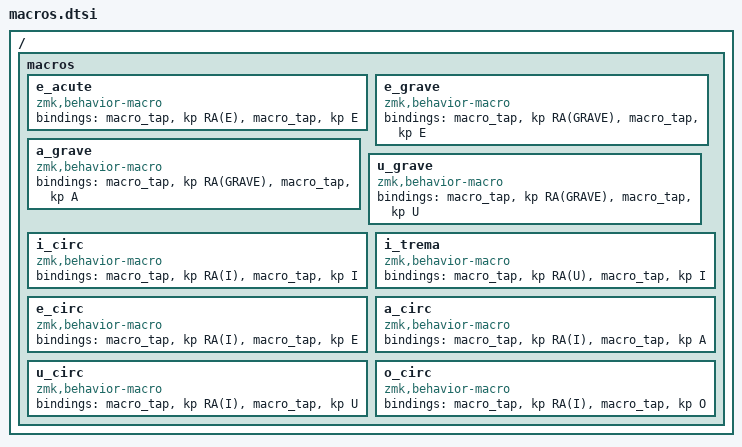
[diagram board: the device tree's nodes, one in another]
// TODO -> Add Windows macros and mark those as MacOS macros

/ {
    macros {
        ///////////////////////////////////
        // ACCENTS
        ///////////////////////////////////
        e_acute: e_acute{ // é
            compatible = "zmk,behavior-macro";
            #binding-cells = <0>;
            bindings
                = <&macro_tap &kp RA(E)>
                , <&macro_tap &kp E>
                ;
        };

        e_grave: e_grave{ // è
            compatible = "zmk,behavior-macro";
            #binding-cells = <0>;
            bindings
                = <&macro_tap &kp RA(GRAVE)>
                , <&macro_tap &kp E>
                ;
        };

        a_grave: a_grave{ // à
            compatible = "zmk,behavior-macro";
            #binding-cells = <0>;
            bindings
                = <&macro_tap &kp RA(GRAVE)>
                , <&macro_tap &kp A>
                ;
        };

        u_grave: u_grave{ // ù
            compatible = "zmk,behavior-macro";
            #binding-cells = <0>;
            bindings
                = <&macro_tap &kp RA(GRAVE)>
                , <&macro_tap &kp U>
                ;
        };

        i_circ: i_circ{ // î
            compatible = "zmk,behavior-macro";
            #binding-cells = <0>;
            bindings
                = <&macro_tap &kp RA(I)>
                , <&macro_tap &kp I>
                ;
        };
        
        i_trema: i_trema{ // ï
            compatible = "zmk,behavior-macro";
            #binding-cells = <0>;
            bindings
                = <&macro_tap &kp RA(U)>
                , <&macro_tap &kp I>
                ;
        };

        e_circ: e_circ{ // ê
            compatible = "zmk,behavior-macro";
            #binding-cells = <0>;
            bindings
                = <&macro_tap &kp RA(I)>
                , <&macro_tap &kp E>
                ;
        };

        a_circ: a_circ{ // â
            compatible = "zmk,behavior-macro";
            #binding-cells = <0>;
            bindings
                = <&macro_tap &kp RA(I)>
                , <&macro_tap &kp A>
                ;
        };

        u_circ: u_circ{ // û
            compatible = "zmk,behavior-macro";
            #binding-cells = <0>;
            bindings
                = <&macro_tap &kp RA(I)>
                , <&macro_tap &kp U>
                ;
        };

        o_circ: o_circ{ // ô
            compatible = "zmk,behavior-macro";
            #binding-cells = <0>;
            bindings
                = <&macro_tap &kp RA(I)>
                , <&macro_tap &kp O>
                ;
        };

        // qu: qu{
        //     label = "qu";
        //     compatible = "zmk,behavior-macro";
        //     #binding-cells = <0>;
        //     bindings
        //         = <&macro_tap &kp Q>
        //         , <&macro_tap &kp U>
        //         ;
        // };
    };
};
